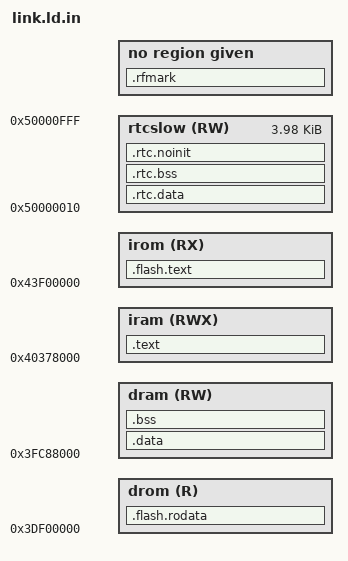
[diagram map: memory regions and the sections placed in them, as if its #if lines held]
#ifndef NDF_APPTRACE
#define NDF_APPTRACE 0        /* 1: app trace over JTAG (trace.h): TRAX blocks 28/29 = 0x3FCE8000-0x3FCEFFFF, DRAM ends 4 KB earlier */
#endif
#define RAM_END (NDF_APPTRACE ? 0x3FCE8000 : 0x3FCE9000)
#ifndef NDF_ULP_RESERVE
#define NDF_ULP_RESERVE 0     /* bytes of RTC slow memory from 0x50000000 for a ULP program (ulp.h) */
#endif
/* ESP32-S3 image (run through the C preprocessor; NDF_XIP, NDF_XIP_ADDR, NDF_XIP_SIZE from the Makefile).
 * RAM part: loaded from flash 0x0 by the ROM loader. Every fetch is single-cycle SRAM -> deterministic.
 * SRAM1 is one memory seen twice: IRAM 0x4037_8000 == DRAM 0x3FC8_8000 (offset 0x6F_0000). Code goes first;
 * data starts right after the code's DRAM alias, so no RAM is wasted on a fixed split. Stay below 0x3FCE9000:
 * the ROM loader's own data lives above it. (0x40370000-0x40377FFF is the instruction cache's SRAM0.)
 * Flash part (NDF_XIP 1 = libraries, 2 = also the application and storage): code in a fixed 1 MB virtual window at
 * 0x43F00000 (MMU entries 496-511, above the 1:1 flash map and the PSRAM window) through the instruction cache, its
 * read-only data right after it at 0x3DF00000 + SIZEOF(code); written to flash as build/<app>/xip.bin. cache.c maps
 * the window onto the running image's flash copy (NDF_XIP_ADDR, or an OTA slot), so one image runs from any slot. */
#define XIP_VWIN 0x1F00000
ENTRY(_start0)

MEMORY
{
    iram (RWX) : ORIGIN = 0x40378000, LENGTH = RAM_END - 0x3FC88000
    dram (RW)  : ORIGIN = 0x3FC88000, LENGTH = RAM_END - 0x3FC88000
    irom (RX)  : ORIGIN = 0x42000000 + XIP_VWIN, LENGTH = NDF_XIP_SIZE
    drom (R)   : ORIGIN = 0x3C000000 + XIP_VWIN, LENGTH = NDF_XIP_SIZE
    rtcslow (RW) : ORIGIN = 0x50000010 + NDF_ULP_RESERVE, LENGTH = 0x1000 - 0x10 - NDF_ULP_RESERVE   /* after the warm-boot jump and the ULP program; 0x50001000+: notes */
}

/* Libraries never called from interrupts, flash operations or the panic path. Kept in RAM on purpose: printf
 * (panic report with the cache off), string (memcpy/memset everywhere), heap, ringbuf, div64, dsp, float, fpu. */
#define XIP_LIB(S) *build?ndf?components?lib?strtod.c.o(S) *build?ndf?components?lib?bigint.c.o(S) *build?ndf?components?lib?stdlib.c.o(S) *build?ndf?components?lib?math.c.o(S) *build?ndf?components?lib?mathf.c.o(S) \
                   *build?ndf?components?lib?double.c.o(S) *build?ndf?components?lib?md5.c.o(S) *build?ndf?components?lib?crc32.c.o(S) *build?ndf?components?lib?p256_comb.c.o(S) *build?ndf?components?lib?ecc.c.o(S) *build?ndf?components?lib?musl?*.c.o(S)
#define XIP_ALL(S) *build?app?*.o(S) *build?ndf?components?drivers?storage?*.o(S) *build?ndf?components?lwip?*.o(S) *build?ndf?components?lwip?lwip?*.o(S) *build?ndf?components?wifi?*.o(S) *build?ndf?components?net?*.o(S) *build?ndf?components?tls?*.o(S)   /* "?" for the slash: no comment opener for cpp */

SECTIONS
{
#if NDF_XIP
    .flash.text : {
        _flash_text_start = ABSOLUTE(.);
        *(.flash.text .flash.text.*)                       /* FLASH_FN */
        XIP_LIB(.literal .literal.* .text .text.*)
#if NDF_XIP == 2
        XIP_ALL(.literal .literal.* .text .text.*)
#endif
        . = ALIGN(16);
        _flash_text_end = ABSOLUTE(.);
    } > irom

    .flash.rodata ORIGIN(drom) + SIZEOF(.flash.text) : {   /* same flash offset as the end of the code */
        _flash_rodata_start = ABSOLUTE(.);
        XIP_LIB(.rodata .rodata.*)
        *build?ndf?components?drivers?rf?rf_init.c.o(.rodata .rodata.*) *build?ndf?components?drivers?rf?rf_wifi.c.o(.rodata .rodata.*)   /* register replay tables (37 KB): read once per init */
#if NDF_XIP == 2
        XIP_ALL(.rodata .rodata.*)
#endif
        . = ALIGN(16);
        _flash_rodata_end = ABSOLUTE(.);
    } > drom
#else
    _flash_text_start = 0; _flash_text_end = 0;
#endif

    .text : {
        KEEP(*(.vectors))                 /* first: VECBASE = 0x40378000, 1 KB aligned */
        *(.iram.literal .iram.text .iram.text.*)
        *(.literal .literal.* .text .text.*)
        . += 16;                          /* the instruction prefetch reads up to 16 B past the last instruction: that must not touch the no-access area */
        . = ALIGN(256);                   /* memprot split line granularity */
        _text_end = .;
    } > iram

    _data_origin = _text_end - 0x6F0000;  /* DRAM alias of the end of code */

    .data _data_origin : {
        *(.rodata .rodata.* .data .data.* .sdata .sdata.*)
        . = ALIGN(4);
        __init_array_start = .;           /* C++ global constructors (and __attribute__((constructor))) */
        KEEP(*(SORT_BY_INIT_PRIORITY(.init_array.*) SORT_BY_INIT_PRIORITY(.ctors.*)))
        KEEP(*(.init_array .ctors))
        __init_array_end = .;
        . = ALIGN(4);                     /* compile-time registries */
        __cmd_start = .;  KEEP(*(SORT_BY_NAME(.ndf_reg.cmd.*)))  __cmd_end = .;    /* cmd.h */
        __test_start = .; KEEP(*(SORT(.ndf_reg.test.*)))         __test_end = .;   /* unit.h, by name */
        _data_end = .;
    } > dram

    .bss (NOLOAD) : ALIGN(16) {
        _bss_start = .;
        *(.bss .bss.* .sbss .sbss.* COMMON)
        . = ALIGN(4);
        _bss_end = .;                     /* stacks stay outside the zeroed range */
        . = ALIGN(16); _stack0_bot = .; . += NDF_STACK0_SIZE; _stack0_top = .;   /* sizes from app.mk (--defsym) */
        . = ALIGN(16); _stack1_bot = .; . += NDF_STACK1_SIZE; _stack1_top = .;
    } > dram

    .rtc.data : { _rtc_data_start = .; *(.rtc.data .rtc.data.*) . = ALIGN(4); _rtc_data_end = .; } > rtcslow
    .rtc.bss (NOLOAD) : { _rtc_bss_start = .; *(.rtc.bss .rtc.bss.*) . = ALIGN(4); _rtc_bss_end = .; } > rtcslow
    .rtc.noinit (NOLOAD) : { *(.rtc.noinit .rtc.noinit.*) } > rtcslow

    .rfmark (NOLOAD) : { *(.rfmark) }    /* non-empty only if the RF dump engine is linked (components/drivers/rf/rf_dump.c) */

    /DISCARD/ : { *(.comment .note.* .eh_frame .xt.prop .xt.prop.* .xtensa.info) }
}

ASSERT(_vector_table == 0x40378000, "vector table must be first in IRAM")
ASSERT(NDF_XIP_SIZE <= 0x100000, "XIP_SIZE: the code window is 1 MB (MMU entries 496-511)")
ASSERT(!NDF_BOOT_FAST || _data_end <= 0x3FCE7E00, "fast boot: the loaded image must end below the loader (0x3FCE7E00)")
ASSERT(_stack1_top <= RAM_END, "RAM full: code + data + stacks exceed SRAM below the ROM loader area (or the trace blocks)")
/* the baseband dump engine writes SRAM banks 0x3FCB0000..0x3FCDFFFF (components/drivers/rf/rf_dump.c) */
ASSERT(SIZEOF(.rfmark) == 0 || _stack1_top <= 0x3FCB0000, "RF dump engine in use: code + data + stacks must end below 0x3FCB0000")
